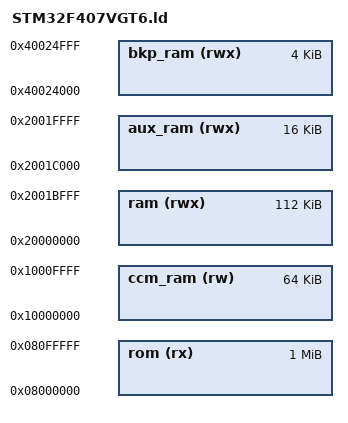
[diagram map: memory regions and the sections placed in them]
SEARCH_DIR(.);

/*
+=============================================================================+
| available memories definitions
+=============================================================================+
*/

MEMORY
{
	rom (rx)		: org = 0x08000000, len = 1M
	ram (rwx)		: org = 0x20000000, len = 112k
	aux_ram (rwx)	: org = 0x2001C000, len = 16k
	ccm_ram (rw)	: org = 0x10000000, len = 64k
	bkp_ram (rwx)	: org = 0x40024000, len = 4k
}

INCLUDE STM32F4xx_memory_map.ld
